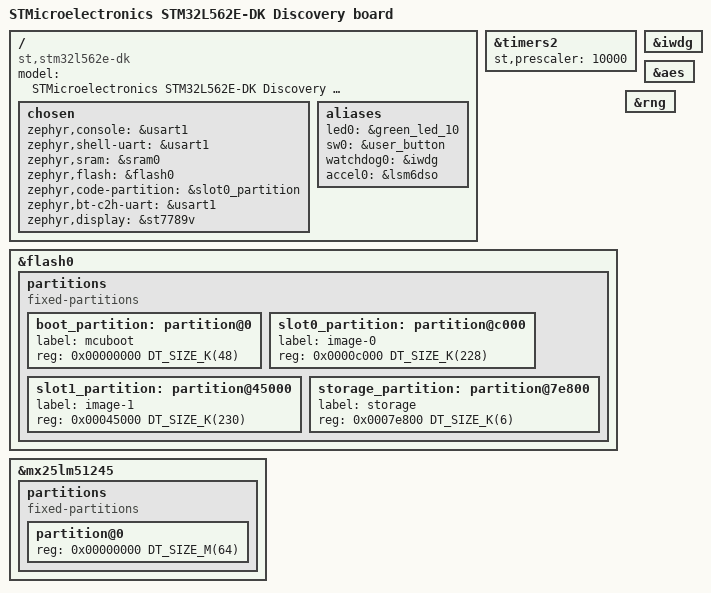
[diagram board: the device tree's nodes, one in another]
/*
 * Copyright (c) 2020 Yestin Sun
 *
 * SPDX-License-Identifier: Apache-2.0
 */

/dts-v1/;
#include "stm32l562e_dk_common.dtsi"

/ {
	model = "STMicroelectronics STM32L562E-DK Discovery board";
	compatible = "st,stm32l562e-dk";

	#address-cells = <1>;
	#size-cells = <1>;

	chosen {
		zephyr,console = &usart1;
		zephyr,shell-uart = &usart1;
		zephyr,sram = &sram0;
		zephyr,flash = &flash0;
		zephyr,code-partition = &slot0_partition;
		zephyr,bt-c2h-uart = &usart1;
		zephyr,display = &st7789v;
	};

	aliases {
		led0 = &green_led_10;
		sw0 = &user_button;
		watchdog0 = &iwdg;
		accel0 = &lsm6dso;
	};
};

&timers2 {
	st,prescaler = <10000>;
};

&iwdg {
	status = "okay";
};

&aes {
	status = "okay";
};

&flash0 {
	partitions {
		compatible = "fixed-partitions";
		#address-cells = <1>;
		#size-cells = <1>;

		boot_partition: partition@0 {
			label = "mcuboot";
			reg = <0x00000000 DT_SIZE_K(48)>;
		};

		slot0_partition: partition@c000 {
			label = "image-0";
			reg = <0x0000c000 DT_SIZE_K(228)>;
		};

		slot1_partition: partition@45000 {
			label = "image-1";
			reg = <0x00045000 DT_SIZE_K(230)>;
		};

		storage_partition: partition@7e800 {
			label = "storage";
			reg = <0x0007e800 DT_SIZE_K(6)>;
		};
	};
};

&mx25lm51245 {
	partitions {
		compatible = "fixed-partitions";
		#address-cells = <1>;
		#size-cells = <1>;

		partition@0 {
			reg = <0x00000000 DT_SIZE_M(64)>;
		};
	};
};

&rng {
	status = "okay";
};
